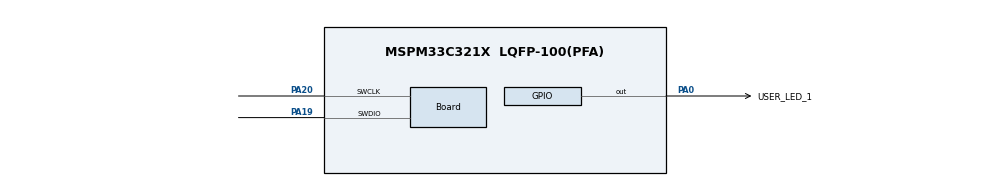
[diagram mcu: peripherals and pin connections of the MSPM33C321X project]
/**
 * @cliArgs --device "MSPM33C321X" --part "Default" --package "LQFP-100(PFA)" --product "mspm33_sdk@1.02.00.00"
 * @versions {"tool":"1.26.0+4407"}
 */
 
/**
 * Import the modules used in this configuration.
 */
const Board  = scripting.addModule("/ti/driverlib/Board");
const GPIO   = scripting.addModule("/ti/driverlib/GPIO", {}, false);
const GPIO1  = GPIO.addInstance();
const SYSCTL = scripting.addModule("/ti/driverlib/SYSCTL");
// @cliArgs --board /ti/boards/LP_MSPM33C321A --rtos freertos

/**
 * Write custom configuration values to the imported modules.
 */
Board.peripheral.$assign          = "DEBUGSS";
Board.peripheral.swclkPin.$assign = "PA20";
Board.peripheral.swdioPin.$assign = "PA19";

GPIO1.$name                               = "GPIO_LEDS";
GPIO1.associatedPins[0].$name             = "USER_LED_1";
GPIO1.associatedPins[0].launchPadShortcut = "LED1En";
GPIO1.associatedPins[0].initialValue      = "SET";
GPIO1.associatedPins[0].pin.$assign       = "PA0";

SYSCTL.peripheral.$assign = "SYSCTL";

const ProjectConfig              = scripting.addModule("/ti/project_config/ProjectConfig", {}, false);
ProjectConfig.genDisable = true;
ProjectConfig.migrationCondition = true;
